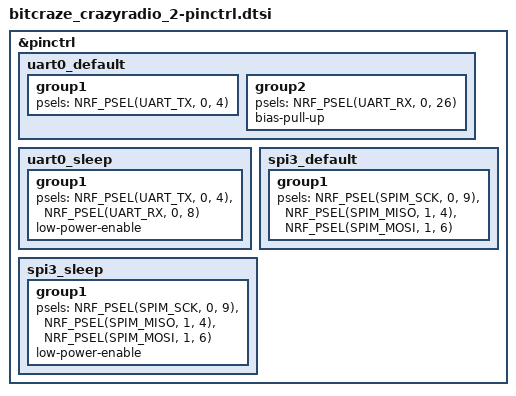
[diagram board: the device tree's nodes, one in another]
/*
 * Copyright (c) 2022 Bitcraze AB
 * Copyright (c) 2022 Nordic Semiconductor
 * SPDX-License-Identifier: Apache-2.0
 */

&pinctrl {
	uart0_default: uart0_default {
		group1 {
			psels = <NRF_PSEL(UART_TX, 0, 4)>;
		};
		group2 {
			psels = <NRF_PSEL(UART_RX, 0, 26)>;
			bias-pull-up;
		};
	};

	uart0_sleep: uart0_sleep {
		group1 {
			psels = <NRF_PSEL(UART_TX, 0, 4)>,
				<NRF_PSEL(UART_RX, 0, 8)>;
			low-power-enable;
		};
	};

	spi3_default: spi3_default {
		group1 {
			psels = <NRF_PSEL(SPIM_SCK, 0, 9)>,
				<NRF_PSEL(SPIM_MISO, 1, 4)>,
				<NRF_PSEL(SPIM_MOSI, 1, 6)>;
		};
	};

	spi3_sleep: spi3_sleep {
		group1 {
			psels = <NRF_PSEL(SPIM_SCK, 0, 9)>,
				<NRF_PSEL(SPIM_MISO, 1, 4)>,
				<NRF_PSEL(SPIM_MOSI, 1, 6)>;
			low-power-enable;
		};
	};

};
